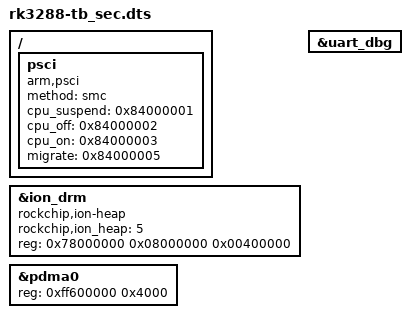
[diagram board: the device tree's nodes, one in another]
// SPDX-License-Identifier: (GPL-2.0+ OR MIT)

#include "rk3288-tb_8846.dts"

/ {
       psci {
               compatible      = "arm,psci";
               method          = "smc";
               cpu_suspend     = <0x84000001>;
               cpu_off         = <0x84000002>;
               cpu_on          = <0x84000003>;
               migrate         = <0x84000005>;
	};
};

&ion_drm {
       compatible = "rockchip,ion-heap";
       rockchip,ion_heap = <5>;
       reg = <0x78000000 0x08000000 0x00400000>;
};

&uart_dbg {
		status = "okay";
		dma-names = "!tx", "!rx";
};

&pdma0 {
		reg = <0xff600000 0x4000>;
};





